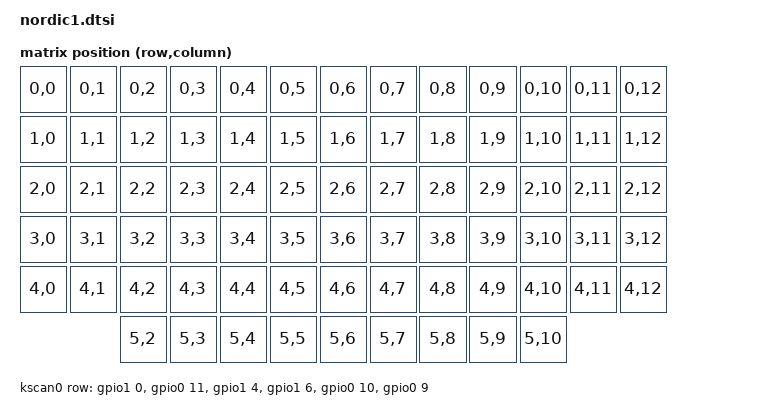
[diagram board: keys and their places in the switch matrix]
// This file was generated from a template. Edit it to match your keyboard.
// See https://zmk.dev/docs/development/hardware-integration/new-shield for more
// instructions.

#include <dt-bindings/zmk/matrix_transform.h>

#include "nordic1-layouts.dtsi"

/ {
    chosen {
        zmk,kscan = &kscan0;
        zmk,physical-layout = &physical_layout0;
    };

    kscan0: kscan0 {
        // If the hardware does not use a switch matrix, change this to the
        // appropriate driver and update the properties below to match.
        // See https://zmk.dev/docs/config/kscan for supported key scan drivers.
        // Set this to "col2row" or "row2col" to match the hardware. If using
        // "row2col", change the col-gpios in the _left.overlay and _right.overlay
        // files to (GPIO_ACTIVE_HIGH | GPIO_PULL_DOWN) and the row-gpios here to
        // GPIO_ACTIVE_HIGH.
        compatible = "zmk,kscan-gpio-matrix";
        diode-direction = "col2row";
        wakeup-source;

        // Replace these comments with the GPIO pins in the matrix.
        // See https://zmk.dev/docs/development/hardware-integration/new-shield#shield-overlays

        row-gpios
            = <&gpio1 0 GPIO_ACTIVE_HIGH>
            , <&gpio0 11 GPIO_ACTIVE_HIGH>
            , <&gpio1 4 GPIO_ACTIVE_HIGH>
            , <&gpio1 6 GPIO_ACTIVE_HIGH>
            , <&gpio0 10 GPIO_ACTIVE_HIGH>
            , <&gpio0 9 GPIO_ACTIVE_HIGH>
        ;
    };

    default_transform: keymap_transform0 {
        // See https://zmk.dev/docs/development/hardware-integration/new-shield#matrix-transform
        // for how to configure this
        compatible = "zmk,matrix-transform";
        columns = <13>;
        rows = <6>;
        

        map = <
            RC(0, 0) RC(0, 1) RC(0, 2) RC(0, 3) RC(0, 4) RC(0, 5)    RC(0, 6) RC(0, 7) RC(0, 8) RC(0, 9) RC(0, 10) RC(0, 11) RC(0, 12)
            RC(1, 0) RC(1, 1) RC(1, 2) RC(1, 3) RC(1, 4) RC(1, 5)    RC(1, 6) RC(1, 7) RC(1, 8) RC(1, 9) RC(1, 10) RC(1, 11) RC(1, 12)
            RC(2, 0) RC(2, 1) RC(2, 2) RC(2, 3) RC(2, 4) RC(2, 5)    RC(2, 6) RC(2, 7) RC(2, 8) RC(2, 9) RC(2, 10) RC(2, 11) RC(2, 12)
            RC(3, 0) RC(3, 1) RC(3, 2) RC(3, 3) RC(3, 4) RC(3, 5)    RC(3, 6) RC(3, 7) RC(3, 8) RC(3, 9) RC(3, 10) RC(3, 11) RC(3, 12)
            RC(4, 0) RC(4, 1) RC(4, 2) RC(4, 3) RC(4, 4) RC(4, 5)    RC(4, 6) RC(4, 7) RC(4, 8) RC(4, 9) RC(4, 10) RC(4, 11) RC(4, 12)
                              RC(5, 2) RC(5, 3) RC(5, 4) RC(5, 5)    RC(5, 6) RC(5, 7) RC(5, 8) RC(5, 9) RC(5, 10)
        >;
    };
};
